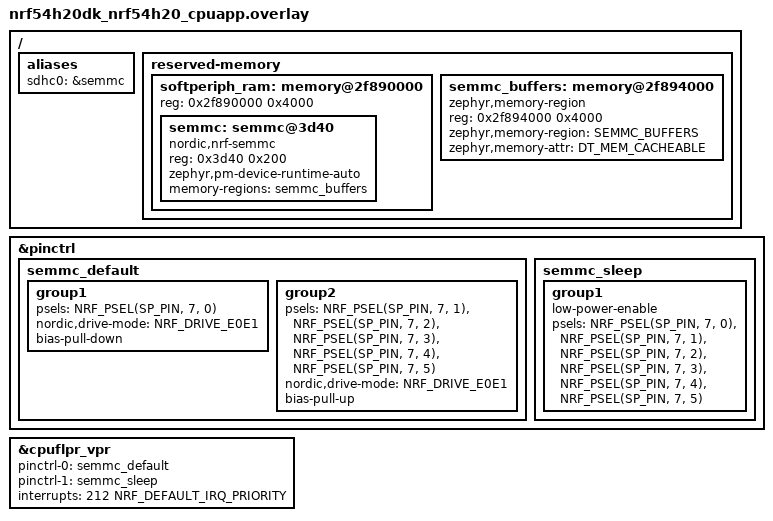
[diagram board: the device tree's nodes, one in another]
/*
 * Copyright (c) 2026 Nordic Semiconductor ASA
 *
 * SPDX-License-Identifier: LicenseRef-Nordic-5-Clause
 */

/ {
	aliases {
		sdhc0 = &semmc;
	};
};

&pinctrl {
	semmc_default: semmc_default {
		group1 {
			psels = <NRF_PSEL(SP_PIN, 7, 0)>; /* CLK */
			nordic,drive-mode = <NRF_DRIVE_E0E1>;
			bias-pull-down;
		};

		group2 {
			psels = <NRF_PSEL(SP_PIN, 7, 1)>, /* D0 */
				<NRF_PSEL(SP_PIN, 7, 2)>, /* D1 */
				<NRF_PSEL(SP_PIN, 7, 3)>, /* D2 */
				<NRF_PSEL(SP_PIN, 7, 4)>, /* D3 */
				<NRF_PSEL(SP_PIN, 7, 5)>; /* CMMD */
			nordic,drive-mode = <NRF_DRIVE_E0E1>;
			bias-pull-up;
		};
	};

	semmc_sleep: semmc_sleep {
		group1 {
			low-power-enable;
			psels = <NRF_PSEL(SP_PIN, 7, 0)>,
				<NRF_PSEL(SP_PIN, 7, 1)>,
				<NRF_PSEL(SP_PIN, 7, 2)>,
				<NRF_PSEL(SP_PIN, 7, 3)>,
				<NRF_PSEL(SP_PIN, 7, 4)>,
				<NRF_PSEL(SP_PIN, 7, 5)>;
		};
	};
};

&cpuflpr_vpr {
	pinctrl-0 = <&semmc_default>;
	pinctrl-1 = <&semmc_sleep>;
	pinctrl-names = "default", "sleep";
	interrupts = <212 NRF_DEFAULT_IRQ_PRIORITY>;
	status = "okay";
	/delete-property/ execution-memory;
};

/delete-node/ &cpuflpr_code_data;
/delete-node/ &cpuapp_cpuflpr_ipc_shm;
/delete-node/ &cpuflpr_cpuapp_ipc_shm;
/delete-node/ &cpuapp_cpuflpr_ipc;

/ {
	reserved-memory {
		softperiph_ram: memory@2f890000 {
			reg = <0x2f890000 0x4000>;
			ranges = <0 0x2f890000 0x4000>;
			#address-cells = <1>;
			#size-cells = <1>;

			semmc: semmc@3d40 {
				compatible = "nordic,nrf-semmc";
				#address-cells = <1>;
				#size-cells = <0>;
				reg = <0x3d40 0x200>;
				zephyr,pm-device-runtime-auto;
				memory-regions = <&semmc_buffers>;
			};
		};

		semmc_buffers: memory@2f894000 {
			compatible = "zephyr,memory-region";
			reg = <0x2f894000 0x4000>;
			#memory-region-cells = <0>;
			zephyr,memory-region = "SEMMC_BUFFERS";
			zephyr,memory-attr = <DT_MEM_CACHEABLE>;
		};
	};
};
